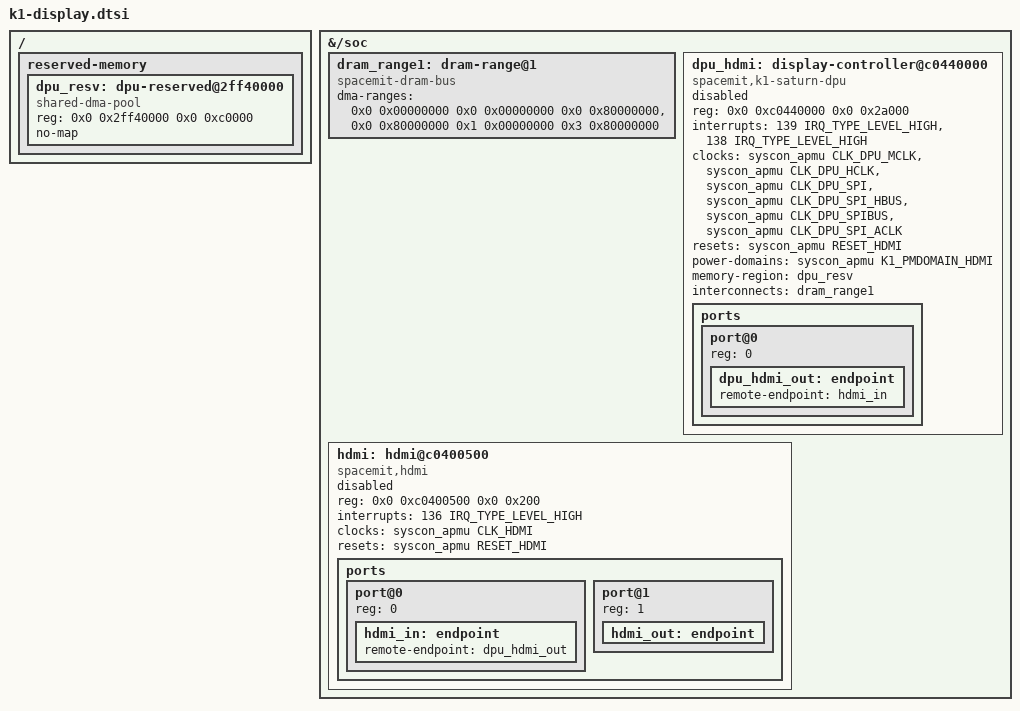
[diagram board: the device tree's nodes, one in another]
// SPDX-License-Identifier: (GPL-2.0 OR MIT)
/*
 * SpacemiT K1 HDMI display subsystem: DPU1 (the ONLINE2 compositor) feeding
 * the integrated HDMI transmitter.
 *
 * The DPU needs two pieces of board integration that are not part of the SoC
 * description proper:
 *
 *   - a dedicated DMA pool for its MMU tables and command lists, which the
 *     command-list fetch engine can read (generic CMA memory does not work)
 *   - the DMA range window of the display master, so the DMA API translates
 *     and bounds the addresses it hands out
 */

#include <dt-bindings/clock/spacemit,k1-syscon.h>
#include <dt-bindings/interrupt-controller/irq.h>
#include <dt-bindings/power/spacemit,k1-power.h>

/ {
	reserved-memory {
		#address-cells = <2>;
		#size-cells = <2>;
		ranges;

		/*
		 * 768K of uncached DRAM handed straight to the display
		 * controller: MMU tables (256K) and command lists (128K) live
		 * here, so the block never fetches them from cacheable memory.
		 */
		dpu_resv: dpu-reserved@2ff40000 {
			compatible = "shared-dma-pool";
			reg = <0x0 0x2ff40000 0x0 0xc0000>;
			no-map;
		};
	};
};

&{/soc} {
	/*
	 * DMA window seen by the VPU/GPU/DPU: the low 2GB is identity mapped
	 * and the RAM above 4GB folds into the 0x80000000 window.  Masters
	 * pick this up through the "dma-mem" interconnect path.
	 */
	dram_range1: dram-range@1 {
		compatible = "spacemit-dram-bus";
		#address-cells = <2>;
		#size-cells = <2>;
		dma-ranges = <0x0 0x00000000 0x0 0x00000000 0x0 0x80000000>,
			     <0x0 0x80000000 0x1 0x00000000 0x3 0x80000000>;
		#interconnect-cells = <0>;
		status = "okay";
	};

	dpu_hdmi: display-controller@c0440000 {
		compatible = "spacemit,k1-saturn-dpu";
		reg = <0x0 0xc0440000 0x0 0x2a000>;
		interrupts = <139 IRQ_TYPE_LEVEL_HIGH>,
			     <138 IRQ_TYPE_LEVEL_HIGH>;
		interrupt-names = "online", "offline";
		clocks = <&syscon_apmu CLK_DPU_MCLK>,
			 <&syscon_apmu CLK_DPU_HCLK>,
			 <&syscon_apmu CLK_DPU_SPI>,
			 <&syscon_apmu CLK_DPU_SPI_HBUS>,
			 <&syscon_apmu CLK_DPU_SPIBUS>,
			 <&syscon_apmu CLK_DPU_SPI_ACLK>;
		clock-names = "mclk", "hclk", "spiclk", "spi_hbus",
			      "spibus", "spi_aclk";
		resets = <&syscon_apmu RESET_HDMI>;
		reset-names = "hdmi_reset";
		power-domains = <&syscon_apmu K1_PMDOMAIN_HDMI>;
		memory-region = <&dpu_resv>;
		interconnects = <&dram_range1>;
		interconnect-names = "dma-mem";
		status = "disabled";

		ports {
			#address-cells = <1>;
			#size-cells = <0>;

			port@0 {
				reg = <0>;
				dpu_hdmi_out: endpoint {
					remote-endpoint = <&hdmi_in>;
				};
			};
		};
	};

	hdmi: hdmi@c0400500 {
		compatible = "spacemit,hdmi";
		reg = <0x0 0xc0400500 0x0 0x200>;
		interrupts = <136 IRQ_TYPE_LEVEL_HIGH>;
		clocks = <&syscon_apmu CLK_HDMI>;
		clock-names = "hmclk";
		resets = <&syscon_apmu RESET_HDMI>;
		reset-names = "hdmi_reset";
		status = "disabled";

		ports {
			#address-cells = <1>;
			#size-cells = <0>;

			port@0 {
				reg = <0>;
				hdmi_in: endpoint {
					remote-endpoint = <&dpu_hdmi_out>;
				};
			};

			port@1 {
				reg = <1>;
				hdmi_out: endpoint {
				};
			};
		};
	};
};
